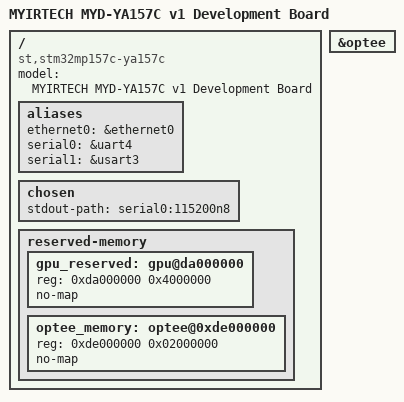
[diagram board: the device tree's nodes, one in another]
// SPDX-License-Identifier: (GPL-2.0+ OR BSD-3-Clause)
/*
 * Copyright (C) STMicroelectronics 2018 - All Rights Reserved
 * Author: Alexandre Torgue <alexandre.torgue@st.com>.
 */

/dts-v1/;

#include "stm32mp157.dtsi"
#include "stm32mp15xa.dtsi"
#include "stm32mp157-pinctrl.dtsi"
#include "stm32mp15xxac-pinctrl.dtsi"
#include "stm32mp15xx-ya157c.dtsi"

/ {
	model = "MYIRTECH MYD-YA157C v1 Development Board";
	compatible = "st,stm32mp157c-ya157c", "st,stm32mp157";

		
	aliases {
		ethernet0 = &ethernet0;
		serial0 = &uart4;
		serial1 = &usart3;
		//serial2 = &uart7;
	};

	chosen {
		stdout-path = "serial0:115200n8";
	};

	reserved-memory {
		gpu_reserved: gpu@da000000 {
			reg = <0xda000000 0x4000000>;
			no-map;
		};

		optee_memory: optee@0xde000000 {
			reg = <0xde000000 0x02000000>;
			no-map;
		};
	};
	
};

&optee {
	status = "okay";
};

